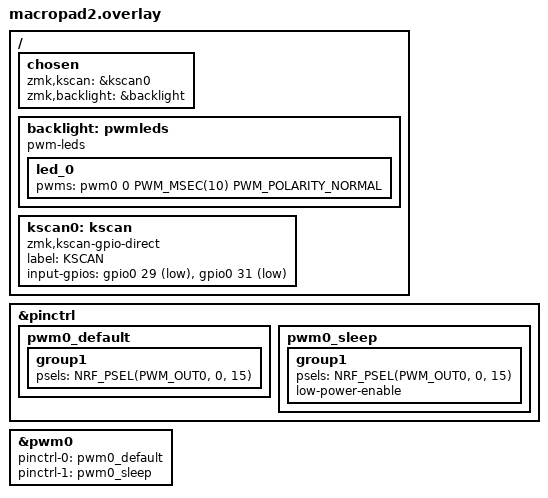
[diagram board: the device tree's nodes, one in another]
&pinctrl {
    pwm0_default: pwm0_default {
        group1 {
            psels = <NRF_PSEL(PWM_OUT0, 0, 15)>; /* LED bawaan nice!nano */
        };
    };
    pwm0_sleep: pwm0_sleep {
        group1 {
            psels = <NRF_PSEL(PWM_OUT0, 0, 15)>;
            low-power-enable;
        };
    };
};

&pwm0 {
    status = "okay";
    pinctrl-0 = <&pwm0_default>;
    pinctrl-1 = <&pwm0_sleep>;
    pinctrl-names = "default", "sleep";
};

/ {
    chosen {
        zmk,kscan = &kscan0;
        zmk,backlight = &backlight;
        /delete-property/ zmk,led-indicators;
    };

    backlight: pwmleds {
        compatible = "pwm-leds";
        led_0 {
            pwms = <&pwm0 0 PWM_MSEC(10) PWM_POLARITY_NORMAL>;
        };
    };

    kscan0: kscan {
        compatible = "zmk,kscan-gpio-direct";
        label = "KSCAN";
        input-gpios
            = <&gpio0 29 (GPIO_ACTIVE_LOW | GPIO_PULL_UP)>   /* D15 - Tombol 1: Enter */
            , <&gpio0 31 (GPIO_ACTIVE_LOW | GPIO_PULL_UP)>   /* D16 - Tombol 2: Mute  */
            ;
    };
};
